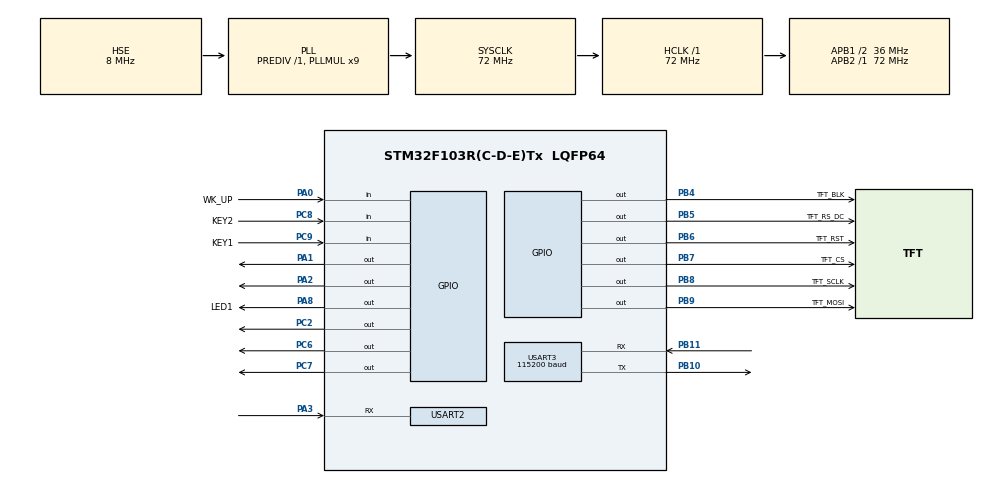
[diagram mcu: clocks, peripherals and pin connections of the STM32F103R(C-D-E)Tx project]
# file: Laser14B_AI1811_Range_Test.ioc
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Mcu.Family=STM32F1
Mcu.Name=STM32F103R(C-D-E)Tx
Mcu.Package=LQFP64
NVIC.PriorityGroup=NVIC_PRIORITYGROUP_4
PA0-WKUP.GPIO_Label=WK_UP
PA0-WKUP.GPIO_PuPd=GPIO_PULLDOWN
PA0-WKUP.Signal=GPIO_Input
PA3.Mode=Asynchronous
PA3.Signal=USART2_RX
PA13.Mode=Serial_Wire
PA13.Signal=SYS_JTMS-SWDIO
PA14.Mode=Serial_Wire
PA14.Signal=SYS_JTCK-SWCLK
PA8.GPIO_Label=LED1
PA8.Signal=GPIO_Output
PB10.Mode=Asynchronous
PB10.Signal=USART3_TX
PB11.Mode=Asynchronous
PB11.Signal=USART3_RX
PC8.GPIO_Label=KEY2
PC8.GPIO_PuPd=GPIO_PULLUP
PC8.Signal=GPIO_Input
PC9.GPIO_Label=KEY1
PC9.GPIO_PuPd=GPIO_PULLUP
PC9.Signal=GPIO_Input
PD0-OSC_IN.Mode=HSE-External-Oscillator
PD0-OSC_IN.Signal=RCC_OSC_IN
PD1-OSC_OUT.Mode=HSE-External-Oscillator
PD1-OSC_OUT.Signal=RCC_OSC_OUT
ProjectManager.HeapSize=0x200
ProjectManager.StackSize=0x400
ProjectManager.TargetToolchain=MDK-ARM V5.32
RCC.AHBFreq_Value=72000000
RCC.APB1CLKDivider=RCC_HCLK_DIV2
RCC.APB1Freq_Value=36000000
RCC.APB1TimFreq_Value=72000000
RCC.APB2Freq_Value=72000000
RCC.APB2TimFreq_Value=72000000
RCC.HCLKFreq_Value=72000000
RCC.PLLMUL=RCC_PLL_MUL9
RCC.PLLSourceVirtual=RCC_PLLSOURCE_HSE
RCC.SYSCLKFreq_VALUE=72000000
RCC.SYSCLKSource=RCC_SYSCLKSOURCE_PLLCLK
RCC.USBFreq_Value=72000000
USART2.BaudRate=115200
USART2.Mode=RX
USART2.Parity=PARITY_NONE
USART2.StopBits=STOPBITS_1
USART2.VirtualMode=VM_ASYNC
USART2.WordLength=WORDLENGTH_8B
USART3.BaudRate=115200
USART3.Mode=TX_RX
USART3.Parity=PARITY_NONE
USART3.StopBits=STOPBITS_1
USART3.VirtualMode=VM_ASYNC
USART3.WordLength=WORDLENGTH_8B
board=custom
PA1.Signal=GPIO_Output
PA1.PinState=GPIO_PIN_RESET
PA2.Signal=GPIO_Output
PA2.PinState=GPIO_PIN_RESET
PB4.GPIO_Label=TFT_BLK
PB4.PinState=GPIO_PIN_RESET
PB4.Signal=GPIO_Output
PB5.GPIO_Label=TFT_RS_DC
PB5.PinState=GPIO_PIN_RESET
PB5.Signal=GPIO_Output
PB6.GPIO_Label=TFT_RST
PB6.PinState=GPIO_PIN_RESET
PB6.Signal=GPIO_Output
PB7.GPIO_Label=TFT_CS
PB7.PinState=GPIO_PIN_RESET
PB7.Signal=GPIO_Output
PB8.GPIO_Label=TFT_SCLK
PB8.PinState=GPIO_PIN_RESET
PB8.Signal=GPIO_Output
PB9.GPIO_Label=TFT_MOSI
PB9.PinState=GPIO_PIN_RESET
PB9.Signal=GPIO_Output
PC2.Signal=GPIO_Output
PC2.PinState=GPIO_PIN_RESET
PC6.Signal=GPIO_Output
PC6.PinState=GPIO_PIN_RESET
PC7.Signal=GPIO_Output
PC7.PinState=GPIO_PIN_RESET

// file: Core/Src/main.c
/* Derived from the verified 12B RX-only project; standalone stationary test. */
#include "main.h"
/* USER CODE BEGIN Includes */
#include "RangeTest.h"
#include "StationaryGuard.h"
/* USER CODE END Includes */
UART_HandleTypeDef huart2;
UART_HandleTypeDef huart3;
void SystemClock_Config(void);
static void MX_GPIO_Init(void);
static void MX_USART2_UART_Init(void);
static void MX_USART3_UART_Init(void);
int main(void)
{
  HAL_Init();
  /* USER CODE BEGIN Init */
  StationaryGuard_Init();
  /* USER CODE END Init */
  SystemClock_Config();
  MX_GPIO_Init();
  MX_USART2_UART_Init();
  MX_USART3_UART_Init();
  /* USER CODE BEGIN 2 */
  RangeTest_Init();
  /* USER CODE END 2 */
  while (1)
  {
    /* USER CODE BEGIN 3 */
    RangeTest_Task();
    /* USER CODE END 3 */
  }
}
void SystemClock_Config(void)
{
  RCC_OscInitTypeDef RCC_OscInitStruct = {0};
  RCC_ClkInitTypeDef RCC_ClkInitStruct = {0};

  RCC_OscInitStruct.OscillatorType = RCC_OSCILLATORTYPE_HSE;
  RCC_OscInitStruct.HSEState = RCC_HSE_ON;
  RCC_OscInitStruct.HSEPredivValue = RCC_HSE_PREDIV_DIV1;
  RCC_OscInitStruct.HSIState = RCC_HSI_ON;
  RCC_OscInitStruct.PLL.PLLState = RCC_PLL_ON;
  RCC_OscInitStruct.PLL.PLLSource = RCC_PLLSOURCE_HSE;
  RCC_OscInitStruct.PLL.PLLMUL = RCC_PLL_MUL9;
  if (HAL_RCC_OscConfig(&RCC_OscInitStruct) != HAL_OK)
  {
    Error_Handler();
  }

  RCC_ClkInitStruct.ClockType = RCC_CLOCKTYPE_HCLK | RCC_CLOCKTYPE_SYSCLK |
                                RCC_CLOCKTYPE_PCLK1 | RCC_CLOCKTYPE_PCLK2;
  RCC_ClkInitStruct.SYSCLKSource = RCC_SYSCLKSOURCE_PLLCLK;
  RCC_ClkInitStruct.AHBCLKDivider = RCC_SYSCLK_DIV1;
  RCC_ClkInitStruct.APB1CLKDivider = RCC_HCLK_DIV2;
  RCC_ClkInitStruct.APB2CLKDivider = RCC_HCLK_DIV1;
  if (HAL_RCC_ClockConfig(&RCC_ClkInitStruct, FLASH_LATENCY_2) != HAL_OK)
  {
    Error_Handler();
  }
}

static void MX_USART2_UART_Init(void)
{
  huart2.Instance = USART2;
  huart2.Init.BaudRate = 115200;
  huart2.Init.WordLength = UART_WORDLENGTH_8B;
  huart2.Init.StopBits = UART_STOPBITS_1;
  huart2.Init.Parity = UART_PARITY_NONE;
  huart2.Init.Mode = UART_MODE_RX;
  huart2.Init.HwFlowCtl = UART_HWCONTROL_NONE;
  huart2.Init.OverSampling = UART_OVERSAMPLING_16;
  if (HAL_UART_Init(&huart2) != HAL_OK)
  {
    Error_Handler();
  }
}

static void MX_USART3_UART_Init(void)
{
  huart3.Instance = USART3;
  huart3.Init.BaudRate = 115200;
  huart3.Init.WordLength = UART_WORDLENGTH_8B;
  huart3.Init.StopBits = UART_STOPBITS_1;
  huart3.Init.Parity = UART_PARITY_NONE;
  huart3.Init.Mode = UART_MODE_TX_RX;
  huart3.Init.HwFlowCtl = UART_HWCONTROL_NONE;
  huart3.Init.OverSampling = UART_OVERSAMPLING_16;
  if (HAL_UART_Init(&huart3) != HAL_OK)
  {
    Error_Handler();
  }
}

static void MX_GPIO_Init(void)
{
  GPIO_InitTypeDef GPIO_InitStruct = {0};

  __HAL_RCC_GPIOA_CLK_ENABLE();
  __HAL_RCC_GPIOB_CLK_ENABLE();

  HAL_GPIO_WritePin(GPIOB,
                    TFT_BLK_Pin | TFT_RS_DC_Pin | TFT_RST_Pin |
                    TFT_CS_Pin | TFT_SCLK_Pin | TFT_MOSI_Pin,
                    GPIO_PIN_RESET);

  GPIO_InitStruct.Pin = TFT_BLK_Pin | TFT_RS_DC_Pin | TFT_RST_Pin |
                        TFT_CS_Pin | TFT_SCLK_Pin | TFT_MOSI_Pin;
  GPIO_InitStruct.Mode = GPIO_MODE_OUTPUT_PP;
  GPIO_InitStruct.Pull = GPIO_NOPULL;
  GPIO_InitStruct.Speed = GPIO_SPEED_FREQ_HIGH;
  HAL_GPIO_Init(GPIOB, &GPIO_InitStruct);
}

void Error_Handler(void)
{
  StationaryGuard_Init();
  __disable_irq();
  while (1) { }
}
